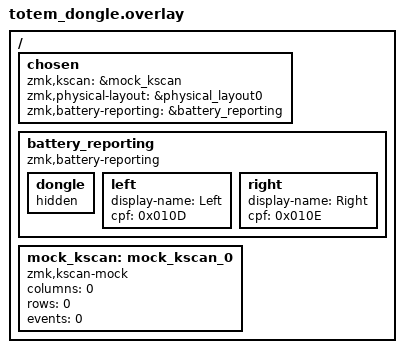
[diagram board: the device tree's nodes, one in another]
/*
* Copyright (c) 2022 The ZMK Contributors
*
* SPDX-License-Identifier: MIT
*/
#include <dt-bindings/zmk/matrix_transform.h>
#include "totem-layouts.dtsi"

/ {
    chosen {
        zmk,kscan = &mock_kscan;
        zmk,physical-layout = &physical_layout0;
        zmk,battery-reporting = &battery_reporting;
    };

    battery_reporting: battery_reporting {
        compatible = "zmk,battery-reporting";

        dongle {
            hidden;
        };
        left {
            display-name = "Left";
            cpf = <0x010D>;
        };
        right {
            display-name = "Right";
            cpf = <0x010E>;
        };
    };

    mock_kscan: mock_kscan_0 {
        compatible = "zmk,kscan-mock";
        columns = <0>;
        rows = <0>;
        events = <0>;
    };
};
